# WB32F10x register map
File version: 1.2
CPU: CM3 r2p0, little endian, MPU, no FPU, 4 interrupt priority bits
Registers are 32-bit, read-write, reset 0x0 unless marked. A register's access mark holds for its fields unless they carry their own. Offsets are from the block's base; [hi:lo] are bit positions; {n}, {i} and the like mark numbered series.

## GPIOA — General-purpose and alternate-function I/O
Base 0x40000000
Same registers: GPIOB 0x40000400, GPIOC 0x40000800, GPIOD 0x40000C00
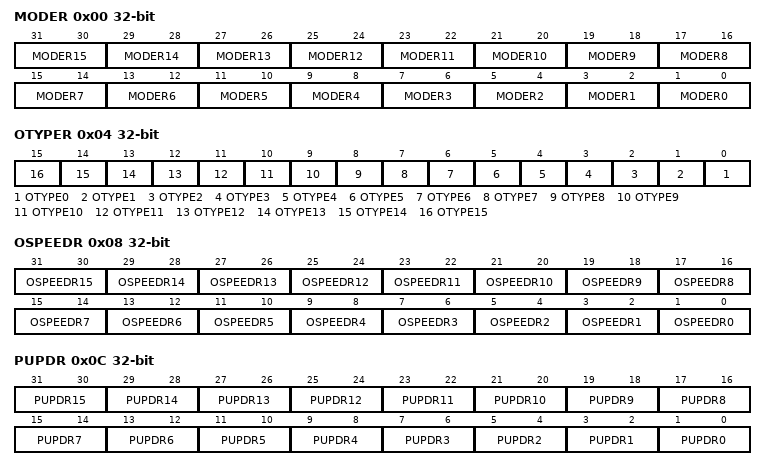
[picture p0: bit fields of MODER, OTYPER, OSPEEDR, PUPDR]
0x00 MODER — GPIO port mode register
  [2n+1:2n] MODER{n} (n=0..15) — Port x configuration bits {n}
    0=Input mode; 1=Output (General purpose output mode); 2=Alternate function mode; 3=Analog mode
0x04 OTYPER — GPIO port output type register
  [n] OTYPE{n} (n=0..15) — Port x configuration bits {n}
    0=Push_Pull (Output push pull); 1=Open_Drain (Output open drain)
0x08 OSPEEDR — GPIO port output speed register
  [2n+1:2n] OSPEEDR{n} (n=0..15) — Port x configuration bits {n}
    0=Speed (High speed); 1=Speed (Low speed)
0x0C PUPDR — GPIO port pull-up/pull-down register
  [2n+1:2n] PUPDR{n} (n=0..15) — Port x configuration bits {n}
    0=Pull (No pull-up or pull-down); 1=Pull-up; 1=Pull-down; 3=Pull (Reserved)
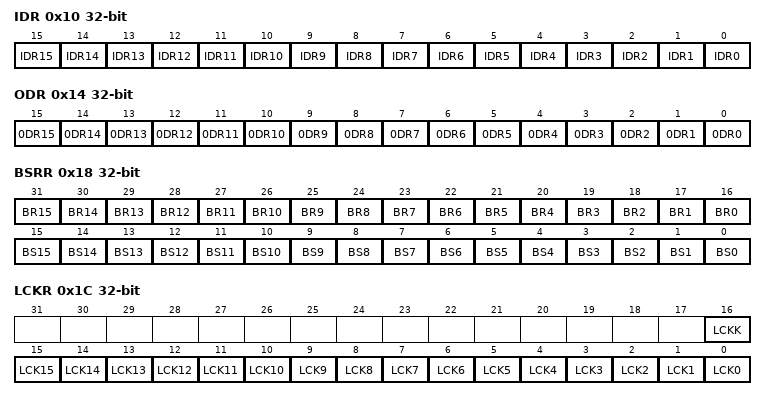
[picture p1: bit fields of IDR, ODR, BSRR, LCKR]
0x10 IDR ro — GPIO port input data register
  [n] IDR{n} (n=0..15) — Port input data {n}
0x14 ODR — GPIO port output data register
  [n] 0DR{n} (n=0..15) — Port putput data {n}
0x18 BSRR write — GPIO port bit set/reset register
  [n+16] BR{n} (n=0..15) — Port x reset bit {n}
  [n] BS{n} (n=0..15) — Port x set bit {n}
0x1C LCKR — GPIO port configuration lock register
  [16] LCKK — This bit can be read any time. It can only be modified using the lock key write sequence
  [n] LCK{n} (n=0..15) — Port x lock bit {n}
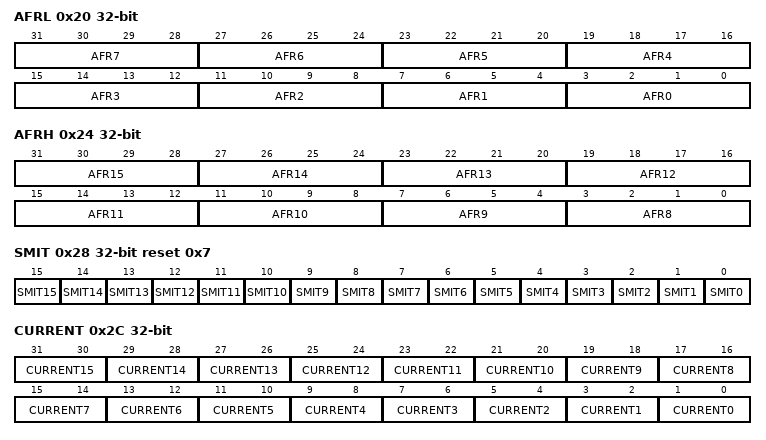
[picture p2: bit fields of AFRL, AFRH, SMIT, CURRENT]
0x20 AFRL — GPIO alternate function low register
  [4n+3:4n] AFR{n} (n=0..7) — Alternate function selection for port x pin {n}
0x24 AFRH — GPIO alternate function high register
  [4n-29:4n-32] AFR{n} (n=8..15) — Alternate function selection for port x pin {n}
0x28 SMIT reset 0x7 — GPIO Port Schmitt Register
  [n] SMIT{n} (n=0..15) — Port x configuration bit {n}
0x2C CURRENT — GPIO Port driver register
  [2n+1:2n] CURRENT{n} (n=0..15) — Port x configuration bits {n}
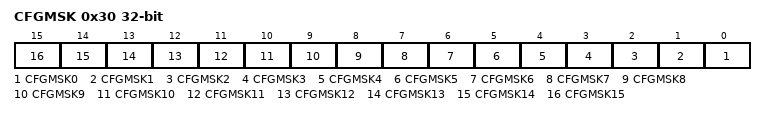
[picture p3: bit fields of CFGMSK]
0x30 CFGMSK — GPIO Port configuration auxiliary register
  [n] CFGMSK{n} (n=0..15) — Port x lock bit {n}

## SYS — System configuration
Base 0x40016400
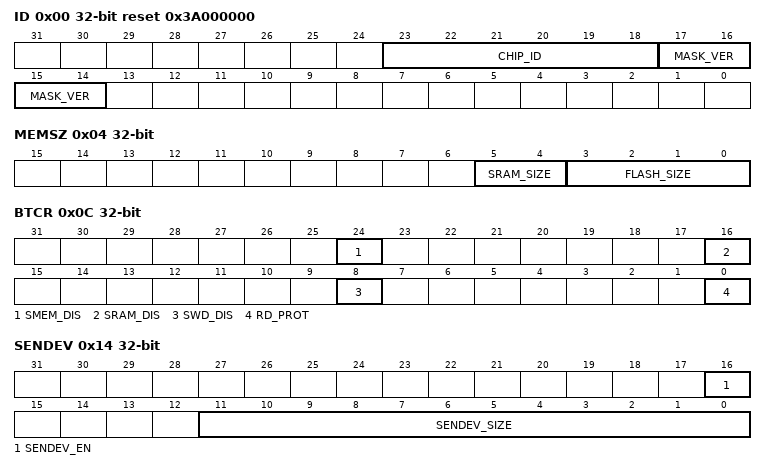
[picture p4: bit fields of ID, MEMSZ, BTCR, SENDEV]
0x00 ID ro reset 0x3A000000 (reset mask 0xFF000000)
  [23:18] CHIP_ID — Part No
  [17:14] MASK_VER — MASK version
0x04 MEMSZ ro reset not defined — Memory control Register
  [5:4] SRAM_SIZE — SRAM density
  [3:0] FLASH_SIZE — FLASH density
0x0C BTCR ro reset not defined — Security control Register
  [24] SMEM_DIS — System memory boot control
  [16] SRAM_DIS — SRAM boot contro
  [8] SWD_DIS — SWD control
  [0] RD_PROT — Read protection control
0x10 MEMWEN ro reset not defined — FLASH write protection register
  [31:0] MAIN_WEN — FLASH Write protection control
0x14 SENDEV ro reset not defined — Secondary development control Register
  [16] SENDEV_EN — Secondary development control
  [11:0] SENDEV_SIZE — Secondary development code space control, the granuality is 1K Byte
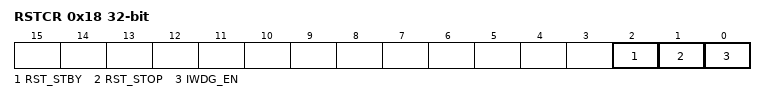
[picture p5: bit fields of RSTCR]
0x18 RSTCR ro (reset mask 0xFFFFFFF0) — Reboot control Register
  [2] RST_STBY — Standby Mode reset control
  [1] RST_STOP — Stop mode reset control
  [0] IWDG_EN — IWDG start control
{0xC+4i} IF{i}LCK ro (reset mask 0xFFFFFFF0) (i=4..7) — Information block {i} protection register
  [0] SYS_IF{i}LCK — {i}th Information block Erase/Write control
0x34 BTSR ro reset 0x2 — Boot control Register
  [1:0] BOOT_MODE

## EXTI — Interrupt/event controller
Base 0x40001800
0x00 IMR — Interrupt mask register
  [18:0] MRx — Interrupt mask on line x
0x04 EMR — Event mask register
  [18:0] MRx — Event mask on line x
0x08 RTSR — Rising edge trigger enable register
  [18:0] TRx — Rising edge trigger enable
0x0C FTSR — Falling edge trigger enable register
  [18:0] TRx — Falling edge trigger enable
0x10 SWIER — Software interrupt event register
  [18:0] SWIERx — Interrupt/Event software trigger
0x14 PR reset not defined — Pending register
  [18:0] PRx — Interrupt pending status
